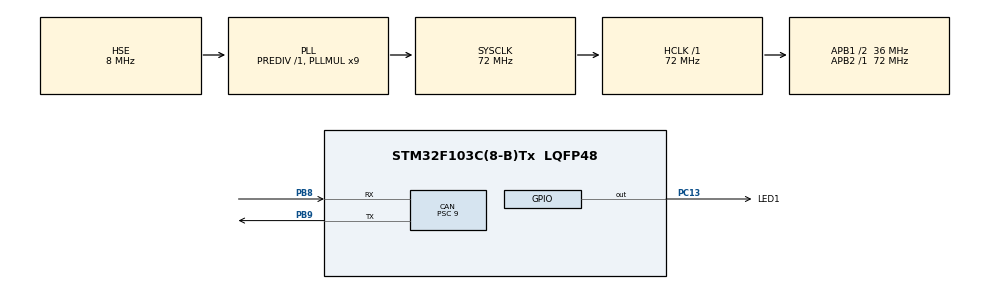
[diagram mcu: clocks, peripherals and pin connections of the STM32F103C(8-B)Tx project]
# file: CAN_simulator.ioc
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CAN.BS1=CAN_BS1_3TQ
CAN.BS2=CAN_BS2_4TQ
CAN.CalculateTimeBit=2000
CAN.CalculateTimeQuantum=250.0
CAN.Prescaler=9
Mcu.Family=STM32F1
Mcu.Name=STM32F103C(8-B)Tx
Mcu.Package=LQFP48
NVIC.PriorityGroup=NVIC_PRIORITYGROUP_4
NVIC.USB_LP_CAN1_RX0_IRQn=true\:0\:0\:false\:false\:true\:true\:true\:true
PA13.Mode=Serial_Wire
PA13.Signal=SYS_JTMS-SWDIO
PA14.Mode=Serial_Wire
PA14.Signal=SYS_JTCK-SWCLK
PB8.Mode=Master
PB8.Signal=CAN_RX
PB9.Mode=Master
PB9.Signal=CAN_TX
PC13-TAMPER-RTC.GPIO_Label=LED1
PC13-TAMPER-RTC.Signal=GPIO_Output
PD0-OSC_IN.Mode=HSE-External-Oscillator
PD0-OSC_IN.Signal=RCC_OSC_IN
PD1-OSC_OUT.Mode=HSE-External-Oscillator
PD1-OSC_OUT.Signal=RCC_OSC_OUT
ProjectManager.HeapSize=0x200
ProjectManager.StackSize=0x400
ProjectManager.TargetToolchain=STM32CubeIDE
RCC.ADCPresc=RCC_ADCPCLK2_DIV6
RCC.AHBFreq_Value=72000000
RCC.APB1CLKDivider=RCC_HCLK_DIV2
RCC.APB1Freq_Value=36000000
RCC.APB1TimFreq_Value=72000000
RCC.APB2Freq_Value=72000000
RCC.APB2TimFreq_Value=72000000
RCC.HCLKFreq_Value=72000000
RCC.PLLMUL=RCC_PLL_MUL9
RCC.PLLSourceVirtual=RCC_PLLSOURCE_HSE
RCC.SYSCLKFreq_VALUE=72000000
RCC.SYSCLKSource=RCC_SYSCLKSOURCE_PLLCLK
RCC.USBFreq_Value=48000000
RCC.USBPrescaler=RCC_USBCLKSOURCE_PLL_DIV1_5
board=custom

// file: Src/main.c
/* USER CODE BEGIN Header */
/**
  ******************************************************************************
  * @file           : main.c
  * @brief          : Main program body
  ******************************************************************************
  * @attention
  *
  * <h2><center>&copy; Copyright (c) 2020 STMicroelectronics.
  * All rights reserved.</center></h2>
  *
  * This software component is licensed by ST under BSD 3-Clause license,
  * the "License"; You may not use this file except in compliance with the
  * License. You may obtain a copy of the License at:
  *                        opensource.org/licenses/BSD-3-Clause
  *
  ******************************************************************************
  */
/* USER CODE END Header */

#include "main.h"

/* USER CODE BEGIN Includes */

#include "PIDs.h"

/* USER CODE END Includes */

/* USER CODE BEGIN PD */

#define RX_ID 0x7DF
#define TX_ID 0x7E8

/* USER CODE END PD */

CAN_HandleTypeDef hcan;

/* USER CODE BEGIN PV */

CAN_RxHeaderTypeDef rxHeader;
CAN_TxHeaderTypeDef txHeader;

CAN_FilterTypeDef canfil;

uint32_t canMailbox;

uint8_t canRX[8];
uint8_t canTX[8];

/* USER CODE END PV */

void SystemClock_Config(void);
static void MX_GPIO_Init(void);
static void MX_CAN_Init(void);
/* USER CODE BEGIN PFP */

float Map (float inVal, float inMin, float inMax, float outMin, float outMax);
void filter_can_config(void);
void send_canmsg(unsigned char pid);
void HAL_CAN_RxFifo0MsgPendingCallback(CAN_HandleTypeDef *hcan);

/* USER CODE END PFP */

int main(void)
{

  /* MCU Configuration--------------------------------------------------------*/

  /* Reset of all peripherals, Initializes the Flash interface and the Systick. */
  HAL_Init();

  /* Configure the system clock */
  SystemClock_Config();

  /* Initialize all configured peripherals */
  MX_GPIO_Init();
  MX_CAN_Init();
  /* USER CODE BEGIN 2 */

	/*----Config filter and start CAN interface------*/
	filter_can_config();
	HAL_CAN_ConfigFilter(&hcan, &canfil);
	HAL_CAN_Start(&hcan);
	//HAL_CAN_ActivateNotification(&hcan, CAN_IT_RX_FIFO0_MSG_PENDING);

	/*----Configure CAN TX messages------------*/
	txHeader.DLC = 8;
	txHeader.IDE = CAN_ID_STD;
	txHeader.RTR = CAN_RTR_DATA;
	txHeader.StdId = TX_ID;
	txHeader.ExtId = 0x02;
	txHeader.TransmitGlobalTime = DISABLE;

  /* USER CODE END 2 */

  /* Infinite loop */
  /* USER CODE BEGIN WHILE */
  while (1)
  {
	//	HAL_CAN_GetRxMessage(&hcan, CAN_RX_FIFO0, &rxHeader, canRX);//Get data from MCU CAN RX buffer (CAN_RX_FIFO0) to our own RX buffer (canRX)
 //   if(rxHeader.StdId == RX_ID) //Verify if RX ID is 0x7DF
    {
				send_canmsg(canRX[2]);  //Call function that send CAN message
				rxHeader.StdId = 0x00;	//Clear RX ID for don't enter in this "if" on next loop
				HAL_Delay(500);					//Some delay for my application not go to fast, we can comment this line for faster messages
		}

    /* USER CODE END WHILE */

  }
}

void SystemClock_Config(void)
{
  RCC_OscInitTypeDef RCC_OscInitStruct = {0};
  RCC_ClkInitTypeDef RCC_ClkInitStruct = {0};

  /** Initializes the CPU, AHB and APB busses clocks
  */
  RCC_OscInitStruct.OscillatorType = RCC_OSCILLATORTYPE_HSE;
  RCC_OscInitStruct.HSEState = RCC_HSE_ON;
  RCC_OscInitStruct.HSEPredivValue = RCC_HSE_PREDIV_DIV1;
  RCC_OscInitStruct.HSIState = RCC_HSI_ON;
  RCC_OscInitStruct.PLL.PLLState = RCC_PLL_ON;
  RCC_OscInitStruct.PLL.PLLSource = RCC_PLLSOURCE_HSE;
  RCC_OscInitStruct.PLL.PLLMUL = RCC_PLL_MUL9;
  if (HAL_RCC_OscConfig(&RCC_OscInitStruct) != HAL_OK)
  {
    Error_Handler();
  }
  /** Initializes the CPU, AHB and APB busses clocks
  */
  RCC_ClkInitStruct.ClockType = RCC_CLOCKTYPE_HCLK|RCC_CLOCKTYPE_SYSCLK
                              |RCC_CLOCKTYPE_PCLK1|RCC_CLOCKTYPE_PCLK2;
  RCC_ClkInitStruct.SYSCLKSource = RCC_SYSCLKSOURCE_PLLCLK;
  RCC_ClkInitStruct.AHBCLKDivider = RCC_SYSCLK_DIV1;
  RCC_ClkInitStruct.APB1CLKDivider = RCC_HCLK_DIV2;
  RCC_ClkInitStruct.APB2CLKDivider = RCC_HCLK_DIV1;

  if (HAL_RCC_ClockConfig(&RCC_ClkInitStruct, FLASH_LATENCY_2) != HAL_OK)
  {
    Error_Handler();
  }
}

static void MX_CAN_Init(void)
{

  hcan.Instance = CAN1;
  hcan.Init.Prescaler = 9;
  hcan.Init.Mode = CAN_MODE_NORMAL;
  hcan.Init.SyncJumpWidth = CAN_SJW_1TQ;
  hcan.Init.TimeSeg1 = CAN_BS1_3TQ;
  hcan.Init.TimeSeg2 = CAN_BS2_4TQ;
  hcan.Init.TimeTriggeredMode = DISABLE;
  hcan.Init.AutoBusOff = DISABLE;
  hcan.Init.AutoWakeUp = DISABLE;
  hcan.Init.AutoRetransmission = DISABLE;
  hcan.Init.ReceiveFifoLocked = DISABLE;
  hcan.Init.TransmitFifoPriority = DISABLE;
  if (HAL_CAN_Init(&hcan) != HAL_OK)
  {
    Error_Handler();
  }

}

static void MX_GPIO_Init(void)
{
  GPIO_InitTypeDef GPIO_InitStruct = {0};

  /* GPIO Ports Clock Enable */
  __HAL_RCC_GPIOC_CLK_ENABLE();
  __HAL_RCC_GPIOD_CLK_ENABLE();
  __HAL_RCC_GPIOA_CLK_ENABLE();
  __HAL_RCC_GPIOB_CLK_ENABLE();

  /*Configure GPIO pin Output Level */
  HAL_GPIO_WritePin(LED1_GPIO_Port, LED1_Pin, GPIO_PIN_RESET);

  /*Configure GPIO pin : LED1_Pin */
  GPIO_InitStruct.Pin = LED1_Pin;
  GPIO_InitStruct.Mode = GPIO_MODE_OUTPUT_PP;
  GPIO_InitStruct.Pull = GPIO_NOPULL;
  GPIO_InitStruct.Speed = GPIO_SPEED_FREQ_LOW;
  HAL_GPIO_Init(LED1_GPIO_Port, &GPIO_InitStruct);

}

/* USER CODE BEGIN 4 */

void HAL_CAN_RxFifo0MsgPendingCallback(CAN_HandleTypeDef *hcan)
{
	HAL_CAN_GetRxMessage(hcan, CAN_RX_FIFO0, &rxHeader, canRX); //Receive CAN bus message to canRX buffer in INTERRUPT MODE
	//HAL_GPIO_TogglePin(LED1_GPIO_Port, LED1_Pin);// toggle PC13 LED
}

void send_canmsg(unsigned char pid)
{
		uint8_t can_msg[8]; //create CAN TX data message
    can_msg[0] = 0x41;  //response header
    can_msg[1] = 0x01;	//mode 1
    can_msg[2] = pid;		//requested PID
		int valA = rand();	//randomic value A
		int valB = rand();	//randomic value B
		int valC = rand();	//randomic value C
		int valD = rand();	//randomic value D
    can_msg[3] = Map(valA, 0, 2147483647, 0, 255); //scale to 8bit value
    can_msg[4] = Map(valB, 0, 2147483647, 0, 255); //scale to 8bit value
		can_msg[5] = Map(valC, 0, 2147483647, 0, 255); //scale to 8bit value
		can_msg[6] = Map(valD, 0, 2147483647, 0, 255); //scale to 8bit value
    can_msg[7] = 0;

		HAL_CAN_AddTxMessage(&hcan, &txHeader, can_msg, &canMailbox);//send TX CAN message
		HAL_GPIO_TogglePin(LED1_GPIO_Port, LED1_Pin);// toggle PC13 LED
}

void filter_can_config()
{
	//https://www.esacademy.com/en/library/calculators/can-best-and-worst-case-calculator.html
	//https://schulz-m.github.io/2017/03/23/stm32-can-id-filter/
	canfil.FilterBank = 0;
	canfil.FilterMode = CAN_FILTERMODE_IDMASK;
	canfil.FilterFIFOAssignment = CAN_RX_FIFO0;

	canfil.FilterIdHigh = ((RX_ID << 5)  | (RX_ID >> (32 - 5))) & 0xFFFF; // STID[10:0] & EXTID[17:13]
	canfil.FilterIdLow = (RX_ID >> (11 - 3)) & 0xFFF8; // EXID[12:5] & 3 Reserved bits

	canfil.FilterMaskIdHigh = ((0x1FFFFFFF << 5)  | (0x1FFFFFFF >> (32 - 5))) & 0xFFFF;
  canfil.FilterMaskIdLow = (0x1FFFFFFF >> (11 - 3)) & 0xFFF8;

	canfil.FilterScale = CAN_FILTERSCALE_32BIT;
	canfil.FilterActivation = ENABLE;
	canfil.SlaveStartFilterBank = 14;
}

float Map (float inVal, float inMin, float inMax, float outMin, float outMax)
{
	return ( (inVal - inMin)*(outMax - outMin)/(inMax - inMin) + outMin );
}

/* USER CODE END 4 */

void Error_Handler(void)
{
}

/************************ (C) COPYRIGHT STMicroelectronics *****END OF FILE****/
